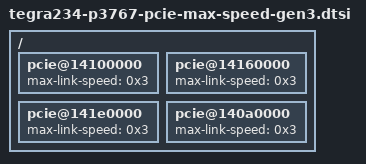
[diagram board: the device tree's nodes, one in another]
/*
 * Copyright (c) 2023, NVIDIA CORPORATION.  All rights reserved.
 *
 * This program is free software; you can redistribute it and/or modify
 * it under the terms of the GNU General Public License as published by
 * the Free Software Foundation; version 2 of the License.
 *
 * This program is distributed in the hope that it will be useful, but WITHOUT
 * ANY WARRANTY; without even the implied warranty of MERCHANTABILITY or
 * FITNESS FOR A PARTICULAR PURPOSE.  See the GNU General Public License for
 * more details.
 */

/ {
	/* C1 X1 */
	pcie@14100000 {
		max-link-speed = <0x3>;
	};

	/* C4 X4 */
	pcie@14160000 {
		max-link-speed = <0x3>;
	};

	/* C7 X8*/
	pcie@141e0000 {
		max-link-speed = <0x3>;
	};

	/* C8 X2 */
	pcie@140a0000 {
		max-link-speed = <0x3>;
	};
};
